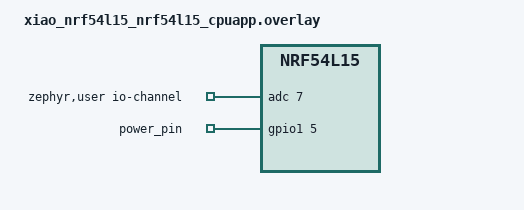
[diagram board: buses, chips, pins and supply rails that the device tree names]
/ {
	aliases {
		power = &power_pin;
	};

	zephyr,user {
		io-channels = <&adc 7>;
	};

	power_outputs {
		compatible = "gpio-leds";

		power_pin: power-pin {
			gpios = <&gpio1 5 GPIO_ACTIVE_HIGH>; /* XIAO D1 */
		};
	};
};

&pdm_imu_pwr {
	/delete-property/ regulator-boot-on;
};

&vbat_pwr {
	/delete-property/ regulator-boot-on;
};
